# rfc_trc_secure register map
Vendor: Texas Instruments
Peripheral module from a debugger description file (folder CC35X1E).
Registers are 32-bit, read-write, reset 0x0 unless marked. A register's access mark holds for its fields unless they carry their own. Offsets are as the file gives them; lines under a group give offsets from that group; [hi:lo] are bit positions; {n}, {i} and the like mark numbered series; 'fields as' and 'values as' point back to an identical list; <NAME> marks a mode.

## rfc_trc_secure
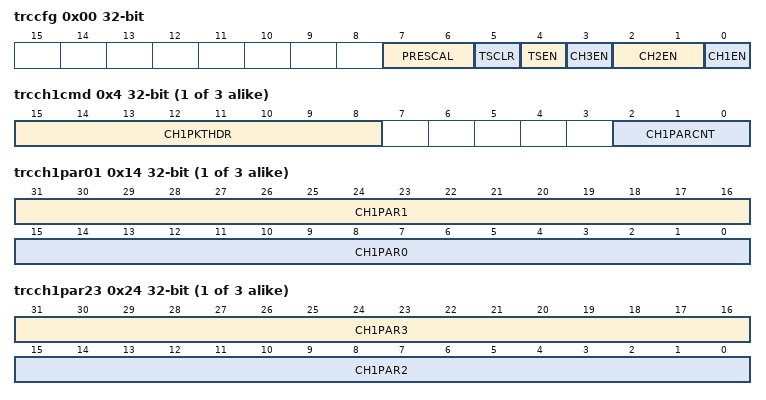
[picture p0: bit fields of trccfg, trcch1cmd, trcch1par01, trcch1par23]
0x00 trccfg access per field — Tracer Configuration
  [7:6] PRESCAL rw — Data rate prescaler for bit clock of the serialized data
    {v}=DIV{v+1} (Divide clock by {v+1}) (v=0..3)
  [5] TSCLR rw — Writing 1 to this bit clears the TX timer
  [4] TSEN rw — Enables the Timestamp
  [3] CH3EN rw — Enables CH3 traces
    0=OFF (Disabled. No tracer transfer due to CH3 events); 1=ENABLED (Enabled in normal mode. Data from bus slave interface.)
  [2:1] CH2EN rw — Enables CH2 traces
    0=OFF (Disabled. No tracer transfer due to CH2 events); 1=NORM (Enabled in normal mode. Data from bus slave interface.); 2=TOPSM (Enabled with MCE and RFE backdoor access access)
  [0] CH1EN rw — Enables CH1 traces
    0=OFF (Disabled. No tracer transfer due to CH1 events); 1=ENABLED (Enabled in normal mode. Data from bus slave interface.)
{0x0+4i} trcch{i}cmd access per field (i=1..3) — Channel {i} Command Register
  [15:8] CH{i}PKTHDR rw — Header Byte. Reverts back to 0 when ready to transmit. A Write starts a transmission sequence.
  [2:0] CH{i}PARCNT rw — Number of parameters to transmit. Reverts back to 0 when ready to transmit. A Write starts a transmission sequence.
{0x10+4i} trcch{i}par01 (i=1..3) — Channel {i} Parameter 0/1 Register
  [31:16] CH{i}PAR1 — Parameter 1 for Channel {i}
  [15:0] CH{i}PAR0 — Parameter 0 for Channel {i}
{0x20+4i} trcch{i}par23 (i=1..3) — Channel {i} Parameter 2/3 Register
  [31:16] CH{i}PAR3 — Parameter 3 for Channel {i}
  [15:0] CH{i}PAR2 — Parameter 2 for Channel {i}
